# RL7005_IP_SVD register map
Vendor: Realtek
Registers are 32-bit, read-write, reset 0x0 unless marked. A register's access mark holds for its fields unless they carry their own. Offsets are from the block's base; [hi:lo] are bit positions; {n}, {i} and the like mark numbered series.

## TRNG_REG
Base 0x41001000
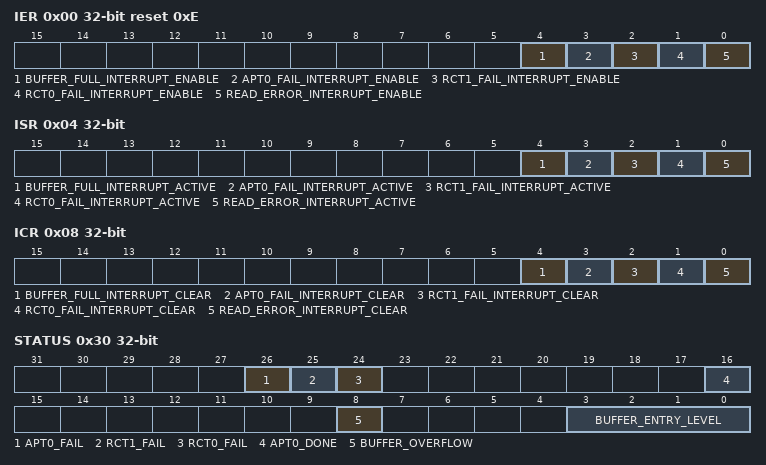
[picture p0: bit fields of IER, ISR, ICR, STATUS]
0x00 IER reset 0xE — Interrupt Enable Register
  [4] BUFFER_FULL_INTERRUPT_ENABLE — RNG buffer full interrupt enable
  [3] APT0_FAIL_INTERRUPT_ENABLE — Adaptive Proportion Test 0 fail interrupt enable
  [2] RCT1_FAIL_INTERRUPT_ENABLE — Repetition Count Test 1 fail interrupt enable
  [1] RCT0_FAIL_INTERRUPT_ENABLE — Repetition Count Test 0 fail interrupt enable
  [0] READ_ERROR_INTERRUPT_ENABLE — Read error interrupt enable. Trigger interrupt when read RNG data register and RNG valid is not 0x1~0x8.
0x04 ISR ro — Interrupt Status Register
  [4] BUFFER_FULL_INTERRUPT_ACTIVE, [3] APT0_FAIL_INTERRUPT_ACTIVE, [2] RCT1_FAIL_INTERRUPT_ACTIVE, [1] RCT0_FAIL_INTERRUPT_ACTIVE, [0] READ_ERROR_INTERRUPT_ACTIVE
0x08 ICR wo — Interrupt Clear Register
  [4] BUFFER_FULL_INTERRUPT_CLEAR
  [3] APT0_FAIL_INTERRUPT_CLEAR — Clear the this interrupt also clear the error flags of APT0 health tests
  [2] RCT1_FAIL_INTERRUPT_CLEAR — Clear the this interrupt also clear the error flags of RCT1 health tests
  [1] RCT0_FAIL_INTERRUPT_CLEAR — Clear the this interrupt also clear the error flags of RCT0 health tests
  [0] READ_ERROR_INTERRUPT_CLEAR
0x0C Valid ro — RNG Valid Register
  [3:0] VALID — Encoded status register. 0x0: buffer empty or APT is not done. 0x1~0x8: number of word is valid. 0xF: APT test fails.
0x10 DATA0 ro — RNG Data Register 0
  [31:0] RANDOM_NUMBER — RNG data register 0. Read as 0x0 if RNG valid register is not a ready status. A Read access triggers a buffer pop, so the value is only read once then be discarded.
0x14 DATA1 ro — RNG Data Register 1
  [31:0] RANDOM_NUMBER — RNG data register 1. Read as 0x0 if RNG valid register is not a ready status. A Read access triggers a buffer pop, so the value is only read once then be discarded.
{0x10+4i} DATA{i} ro (i=3..7) — RNG Data Register {i}
  [31:0] RANDOM_NUMBER — RNG data register {i}. Read as 0x0 if RNG valid register is not a ready status. A Read access triggers a buffer pop, so the value is only read once then be discarded.
0x30 STATUS ro — RNG Status Register
  [26] APT0_FAIL — APT0 error detected
  [25] RCT1_FAIL — RCT1 error detected
  [24] RCT0_FAIL — RCT0 error detected
  [16] APT0_DONE — Adaptive Proportion Test done status. (APT test pass count >= APT done threshold setting)
  [8] BUFFER_OVERFLOW — Buffer overflow status. It is clear by RNG read out.
  [3:0] BUFFER_ENTRY_LEVEL — Number of 32-bit random number are valid. 0: empty 8: full
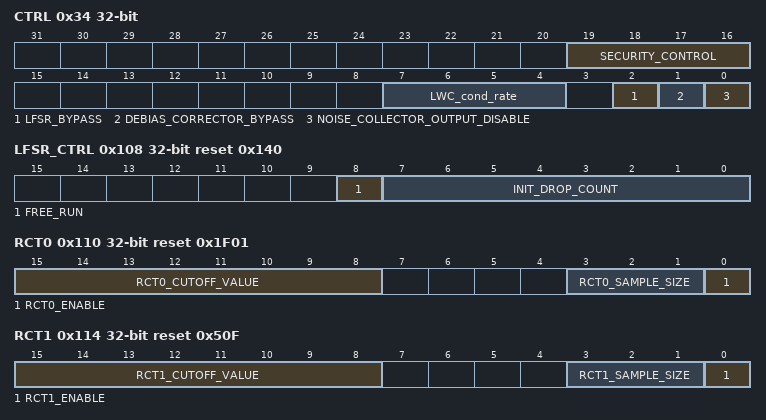
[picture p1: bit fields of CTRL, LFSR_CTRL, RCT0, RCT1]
0x34 CTRL — Control Register
  [19:16] SECURITY_CONTROL — If this field is equal to 0xA, the TRNG becomes a non-secure slave, and all the registers can be accessed by non-secure transaction. If this field is not equal to 0xA, the non-seucre transaction can only access address 0xC~0x30. This register is available only when NONSEC_RNG_BUFFER config is 1 that support TrustZone and dual buffer.
  [7:4] LWC_cond_rate — Compression rate of lightweight-cipher conditioning component. Set this register to 0 will bypass lightweight-cipher conditioning component. Set this register larger than 0 will enable extra trng conditioning. This register is available only when LWC_COND config is 1.
  [2] LFSR_BYPASS — LFSR bypass enable
  [1] DEBIAS_CORRECTOR_BYPASS — Debias corrector bypass enable
  [0] NOISE_COLLECTOR_OUTPUT_DISABLE
0x38 SW_RST wo — Software Reset Register
  [0] SW_RESET — Write 1 to reset TRNG. It triggers a reset generator to reset all the componets of TRNG except control register. The register settings remain unchange, but other function blocks incuding noise collector(ROSC sampler), debias modules and health tests will be reset. When SW changes the setting of RCT/APT, it's recommanded to clear error first, and then wirte this register to trigger a reset after apply new setting.
0x108 LFSR_CTRL reset 0x140 — LFSR Control Register
  [8] FREE_RUN — 0x1: continuously run LFSR when no input data 0x0: only shift LFSR when input 1 bit data
  [7:0] INIT_DROP_COUNT — Discard number of bit after reset or re-init. Default shift out 64 bits in LFSR.
0x110 RCT0 reset 0x1F01 — Repetition Count Test 0 Control Register
  [15:8] RCT0_CUTOFF_VALUE — Cutoff value
  [3:1] RCT0_SAMPLE_SIZE — Number of bit per test sample. The sample size is the value add 1. 0: 1-bit 1: 2-bit ... 7: 8-bit
  [0] RCT0_ENABLE — Test enable
0x114 RCT1 reset 0x50F — Repetition Count Test 1 Control Register
  [15:8] RCT1_CUTOFF_VALUE — Cutoff value
  [3:1] RCT1_SAMPLE_SIZE — Number of bit per test sample. The sample size is the value add 1. 0: 1-bit 1: 2-bit ... 7: 8-bit
  [0] RCT1_ENABLE — Test enable
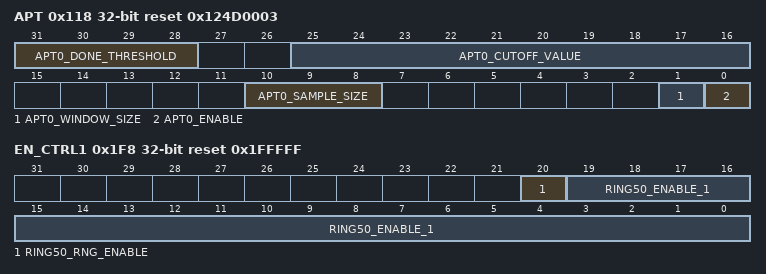
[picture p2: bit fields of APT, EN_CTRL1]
0x118 APT reset 0x124D0003 — Adaptive Proportion Test Control Register
  [31:28] APT0_DONE_THRESHOLD — Assert test done after how many test pass
  [25:16] APT0_CUTOFF_VALUE — Cutoff value
  [10:8] APT0_SAMPLE_SIZE — Number of bit per test sample. The sample size is the value add 1. 0: 1-bit 1: 2-bit ... 7: 8-bit
  [1] APT0_WINDOW_SIZE — 0: 512 bits 1: 1024 bits
  [0] APT0_ENABLE — Test enable
0x1F4 EN_CTRL0 reset 0x3FFFFFFF — Ring Enable Control Register 0
  [29:0] RING50_ENABLE_0 — Enable Ring #29~0
0x1F8 EN_CTRL1 reset 0x1FFFFF — Ring Enable Control Register 1
  [20] RING50_RNG_ENABLE — Enable Ring50 noise source
  [19:0] RING50_ENABLE_1 — Enable Ring #49~30
0x1FC Ring_Sample_CLK_CTRL — Sample clock control register
  [11:8] CLOCK_SAMPLE_RATE_CONTROL — For fine-tune rocs sample clock ROSC sample clock frequency = TRNG APB clock frequency/(Clock sample rate control + 1)
